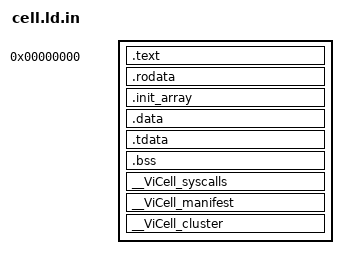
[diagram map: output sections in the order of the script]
/* ViCell Cell Linker Script — Position-Independent Executable (PIE)
 *
 * VA = 0x0 — the kernel loader assigns the actual load base at spawn time.
 * Cells MUST NOT encode a fixed virtual address; the OS is the only party
 * that knows where a cell will live in the Single Address Space.
 *
 * Architecture-specific notes:
 *   .sdata / __global_pointer$ / .sbss  — RISC-V small-data GP optimisation.
 *     On AArch64 and x86_64 no input sections match; the output section is
 *     empty and stripped by lld/ld.  Defining __global_pointer$ is harmless
 *     on non-RISC-V targets (unreferenced symbols are pruned at link time).
 *   __ViCell_syscalls  — x86_64 per-cell syscall allowlist bitmap.
 *     On RISC-V and AArch64 no object provides this section; it is
 *     zero-size and stripped.
 */
ENTRY(main)

SECTIONS
{
    . = 0x0;

    .text : {
        *(.text.boot)
        *(.text .text.*)
    }

    .rodata : ALIGN(4096) {
        *(.rodata .rodata.*)
    }

    .init_array : ALIGN(8) {
        PROVIDE(__init_array_start = .);
        KEEP(*(.init_array .init_array.*))
        PROVIDE(__init_array_end = .);
    }

    .data : ALIGN(4096) {
        /* RISC-V: defines GP base for small-data-pointer optimisation.
         * Unreferenced on AArch64/x86_64 — no cost. */
        PROVIDE(__global_pointer$ = . + 0x800);
        *(.data .data.*)
        *(.data.rel.ro .data.rel.ro.*)
        *(.got .got.* .got.plt)
        *(.sdata .sdata.*)
    }

    /* Thread-local initial image (PT_TLS). One output section keeps the
     * segment start at __tdata_start: .tdata bytes up to __tdata_end, then
     * .tbss zeros up to __tbss_end. __tls_align_mark - __tdata_start is the
     * segment alignment. A runtime that builds per-thread TLS blocks (Rust
     * std's cellos PAL) reads these; PROVIDE_HIDDEN leaves every other cell's
     * symbol table untouched, and a cell without TLS gets no section at all. */
    .tdata : {
        PROVIDE_HIDDEN(__tdata_start = .);
        *(.tdata .tdata.*)
        PROVIDE_HIDDEN(__tdata_end = .);
        *(.tbss .tbss.*)
        *(.tcommon)
        PROVIDE_HIDDEN(__tbss_end = .);
        PROVIDE_HIDDEN(__tls_align_mark = __tdata_start + ALIGNOF(.tdata));
    }

    .bss : ALIGN(4096) {
        __bss_start = .;
        *(.bss .bss.*)
        *(.sbss .sbss.*)
        *(COMMON)
        __bss_end = .;
    }

    /* x86_64: per-cell syscall allowlist bitmap. Zero-size on other arches. */
    __ViCell_syscalls : ALIGN(8) {
        KEEP(*(__ViCell_syscalls))
    }

    /* Cell capability manifest — present in every cell. */
    __ViCell_manifest : ALIGN(4096) {
        KEEP(*(__ViCell_manifest))
    }

    /* Cluster membership declaration (optional, 16 bytes).
     * Absent in cells that do not call declare_cluster! — they default to Isolated. */
    __ViCell_cluster : ALIGN(8) {
        KEEP(*(__ViCell_cluster))
    }
}
